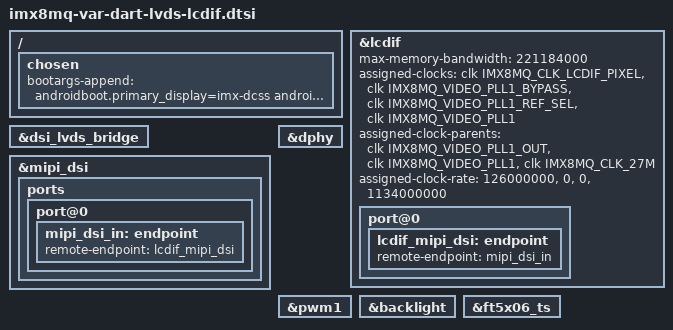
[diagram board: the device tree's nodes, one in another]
// SPDX-License-Identifier: (GPL-2.0 OR MIT)
/*
 * Copyright 2017 NXP
 * Copyright 2018-2020 Variscite Ltd.
 */

/ {
	chosen {
		bootargs-append = "androidboot.primary_display=imx-dcss androidboot.gui_resolution=720p";
	};
};

&lcdif {
	status = "okay";
	max-memory-bandwidth = <221184000>; /* 1280x720-32@60 */

	assigned-clocks = <&clk IMX8MQ_CLK_LCDIF_PIXEL>,
			  <&clk IMX8MQ_VIDEO_PLL1_BYPASS>,
			  <&clk IMX8MQ_VIDEO_PLL1_REF_SEL>,
			  <&clk IMX8MQ_VIDEO_PLL1>;
	assigned-clock-parents = <&clk IMX8MQ_VIDEO_PLL1_OUT>,
				 <&clk IMX8MQ_VIDEO_PLL1>,
				 <&clk IMX8MQ_CLK_27M>;
	assigned-clock-rate = <126000000>, <0>, <0>, <1134000000>;

	port@0 {
		lcdif_mipi_dsi: endpoint {
			remote-endpoint = <&mipi_dsi_in>;
		};
	};
};

&dsi_lvds_bridge {
	status = "okay";
};

&mipi_dsi {
	status = "okay";

	ports {
		port@0 {
			mipi_dsi_in: endpoint {
				remote-endpoint = <&lcdif_mipi_dsi>;
			};
		};
	};
};

&dphy {
	status = "okay";
};

&pwm1 {
	status = "okay";
};

&backlight {
	status = "okay";
};

&ft5x06_ts {
	status = "okay";
};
